# RN831X_RN861X_MCU register map
File version: v0.0.1
CPU: RN831X_RN861X_MCU r1p0, little endian, MPU, no FPU
Registers are 32-bit, read-write, reset 0x0 unless marked. A register's access mark holds for its fields unless they carry their own. Offsets are from the block's base; [hi:lo] are bit positions.

## DAC_CORE0 — DAC
Base 0x20098000
Same registers: DAC_CORE1 0xA0098000
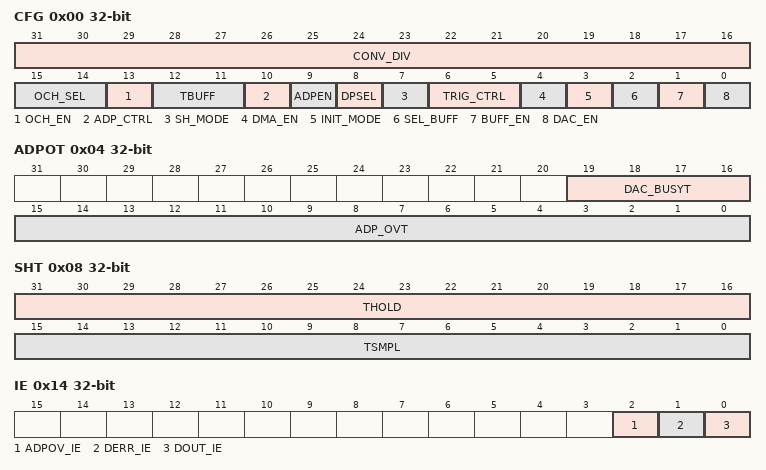
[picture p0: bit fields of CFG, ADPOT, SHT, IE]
0x00 CFG access not given — DAC Control Register
  [31:16] CONV_DIV — Output conversion clock division configuration bits.Toclk=Tsys_clk/(CONV_DIV+1) (refer to user mannual for recommend value )
  [15:14] OCH_SEL — Analog output channel selection bits.
    0=PAD0 (Output to PAD0 (P104)); 1=PAD1 (Output to PAD1 (P140)); 2=ADC0 (Output to ADC0)
  [13] OCH_EN — Analog output channel enable bit.
    0=EN (All output channels are closed;); 1=DIS (Select DAC output to PAD or ADC0 by OCH_SEL;)
  [12:11] TBUFF — Configuration bits for output buffer power-up stabilization wait time(in conversion clock cycles Toclk).
    0=1TOCLK; 1=2TOCLK (2Toclk (default)); 2=3TOCLK; 3=4TOCLK
  [10] ADP_CTRL — Timeout handling method seletion bit, when A/D conversion priority function is enabled
    0=WAITAD_DONE (After timeout ADPOV Flag set as 1, continue waiting until A/D conversion completes, then proceed to next D/A conversion;); 1=ONLYTIMEOUT (After timeout ADPOV Flag set as 1, do not wait for A/D conversion completion, immediately proceed to next D/A conversion;)
  [9] ADPEN — A/D conversion priority function enable bit.
  [8] DPSEL — Data alignment format configuration bit.
    0=RA (Right-aligned data); 1=LA (Left-aligned data)
  [7] SH_MODE — Sample and hold mode enable bit.
    0=NORM (Sample and hold mode disabled, Normal mode;); 1=SPHD (Sample and hold mode enabled;)
  [6:5] TRIG_CTRL — DAC trigger mode configuration bits.
    0=COUTINUE (Continuous output mode;); 1=SWT (Software trigger, writing to DAC_SWT register triggers one conversion;); 2=EXT (External trigger, external trigger source configured by AOS module;)
  [4] DMA_EN — DMA enable bit (when DMA enable,must config TRIG_CTRL as External trigger).
  [3] INIT_MODE — Initial output state selection bit.
    0=HIGHZ (Analog output in high-Z state when channel disabled;); 1=GND (Analog output connected to ground when channel disabled;)
  [2] SEL_BUFF — Output buffer selection enable bit.
    0=BUFF (Output not through buffer;); 1=NO_BUFF (Output through buffer;)
  [1] BUFF_EN — Output buffer enable bit.
  [0] DAC_EN — DAC channel conversion enable bit.
0x04 ADPOT access not given — DAC A/D Conversion Priority Timeout Register
  [19:16] DAC_BUSYT — DAC busy flag assertion time setting bits (in system clock cycles Tsys_clk)
  [15:0] ADP_OVT — A/D conversion priority function timeout configuration bits.(in conversion clock cycles Toclk)
0x08 SHT access not given — DAC Sample Hold Time Register
  [31:16] THOLD — Hold time configuration bits, for sample and hold mode. Hold Time = (THOLD+1)*Toclk
  [15:0] TSMPL — Sampling time configuration bits, for sample and hold mode. Sample Time = (TSMPL+1)*Toclk
0x0C OTRIM access not given — DAC Buffer Calibration Register
  [7:0] OTRIM — (two's complement)When output buffer is enabled, the compensation value for output voltage.
0x10 SWT wo — DAC Software Trigger Register
  [0] SWT — D/A conversion software trigger bit.
0x14 IE — DAC Interrupt Enable Register
  [2] ADPOV_IE — A/D conversion wait timeout interrupt enable bit.
  [1] DERR_IE — DMA error interrupt enable bit.
  [0] DOUT_IE — Data output register update interrupt enable bit.
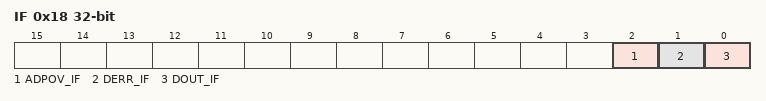
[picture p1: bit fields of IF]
0x18 IF — DAC Interrupt Flag Register
  [2] ADPOV_IF write-1-clears — A/D conversion wait timeout interrupt flag.
  [1] DERR_IF write-1-clears — DMA error interrupt flag.
  [0] DOUT_IF write-1-clears — Data output register update interrupt flag.
0x20 DHOLD access not given — DAC Data Hold Register
  [15:0] DHOLD — When DAC_CFG.DPSEL=0 (data right-aligned), write the data to be converted to DHOLD[11:0];When DAC_CFG.DPSEL=1 (data left-aligned), write the data to be converted to DHOLD[15:4].
0x24 DOUT ro — DAC Data Output Register
  [11:0] DOUT — DAC Data Output bits
